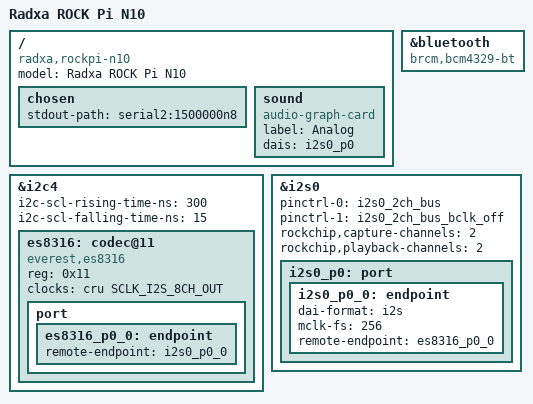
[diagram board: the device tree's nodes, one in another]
// SPDX-License-Identifier: (GPL-2.0+ OR MIT)
/*
 * Copyright (c) 2019 Fuzhou Rockchip Electronics Co., Ltd
 * Copyright (c) 2019 Radxa Limited
 * Copyright (c) 2019 Amarula Solutions(India)
 */

/dts-v1/;
#include "rk3399.dtsi"
#include <arm/rockchip/rockchip-radxa-dalang-carrier.dtsi>
#include "rk3399pro-vmarc-som.dtsi"

/ {
	model = "Radxa ROCK Pi N10";
	compatible = "radxa,rockpi-n10", "vamrs,rk3399pro-vmarc-som",
		     "rockchip,rk3399pro";

	chosen {
		stdout-path = "serial2:1500000n8";
	};

	sound: sound {
		compatible = "audio-graph-card";
		label = "Analog";
		dais = <&i2s0_p0>;
	};
};

&bluetooth {
	compatible = "brcm,bcm4329-bt";
	status = "okay";
};

&i2c4 {
	i2c-scl-rising-time-ns = <300>;
	i2c-scl-falling-time-ns = <15>;
	status = "okay";

	es8316: codec@11 {
		compatible = "everest,es8316";
		reg = <0x11>;
		clocks = <&cru SCLK_I2S_8CH_OUT>;
		clock-names = "mclk";
		#sound-dai-cells = <0>;

		port {
			es8316_p0_0: endpoint {
				remote-endpoint = <&i2s0_p0_0>;
			};
		};
	};
};

&i2s0 {
	pinctrl-0 = <&i2s0_2ch_bus>;
	pinctrl-1 = <&i2s0_2ch_bus_bclk_off>;
	rockchip,capture-channels = <2>;
	rockchip,playback-channels = <2>;
	status = "okay";

	i2s0_p0: port {
		i2s0_p0_0: endpoint {
			dai-format = "i2s";
			mclk-fs = <256>;
			remote-endpoint = <&es8316_p0_0>;
		};
	};
};
